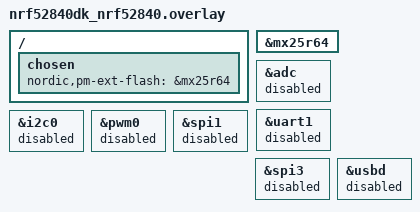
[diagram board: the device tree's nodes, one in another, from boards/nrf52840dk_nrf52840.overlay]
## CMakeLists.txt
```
#
# Copyright (c) 2025 Nordic Semiconductor ASA
#
# SPDX-License-Identifier: LicenseRef-Nordic-5-Clause
#

cmake_minimum_required(VERSION 3.20.0)

include(${CMAKE_CURRENT_LIST_DIR}/../../cmake/find_zephyr.cmake)

project(matter-temperature-sensor)

# NORDIC SDK APP START

# Include all source files that are located in the Matter common directory.
include(${ZEPHYR_NCS_MATTER_MODULE_DIR}/cmake/sample.cmake)

ncs_get_zap_parent_dir(ZAP_PARENT_DIR)

target_include_directories(app PRIVATE
  src
  ${ZAP_PARENT_DIR}
)

target_sources(app PRIVATE
  src/app_task.cpp
  src/main.cpp
)

ncs_configure_data_model()
# NORDIC SDK APP END
```

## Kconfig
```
#
# Copyright (c) 2025 Nordic Semiconductor
#
# SPDX-License-Identifier: LicenseRef-Nordic-5-Clause
#
mainmenu "Matter nRF Connect Temperature Sensor Example Application"

choice OPENTHREAD_NORDIC_LIBRARY_CONFIGURATION
	default OPENTHREAD_NORDIC_LIBRARY_MTD
endchoice

choice OPENTHREAD_DEVICE_TYPE
	default OPENTHREAD_MTD
endchoice

choice OPENTHREAD_IMPLEMENTATION
	default OPENTHREAD_SOURCES
endchoice

config CHIP_ENABLE_ICD_SUPPORT
	default y

config CHIP_ICD_LIT_SUPPORT
	default y

config CHIP_ICD_SIT_SLOW_POLL_LIMIT
	default 5000

config CHIP_ICD_REPORT_ON_ACTIVE_MODE
	default y

# Reduce Thread TX output power to 0 dBm for SED device
config OPENTHREAD_DEFAULT_TX_POWER
	default 0

source "$(ZEPHYR_CONNECTEDHOMEIP_MODULE_DIR)/config/nrfconnect/chip-module/Kconfig.features"
source "$(ZEPHYR_CONNECTEDHOMEIP_MODULE_DIR)/config/nrfconnect/chip-module/Kconfig.defaults"
source "Kconfig.zephyr"
```

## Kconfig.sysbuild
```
#
# Copyright (c) 2025 Nordic Semiconductor ASA
#
# SPDX-License-Identifier: LicenseRef-Nordic-5-Clause
#

#### Radio core selection
config NRF_DEFAULT_IPC_RADIO
	default y

# Enable IEEE802.15.4 serialization to network core
# This config automatically pulls in the `overlay-802154.conf` in the ipc_radio image
config NETCORE_IPC_RADIO_IEEE802154
	default y if SOC_SERIES_NRF53

# Enable Bluetooth serialization to network core
# This config automatically pulls in the `overlay-bt_hci_ipc.conf` in the ipc_radio image
config NETCORE_IPC_RADIO_BT_HCI_IPC
	default y if SOC_SERIES_NRF53

#### Bootloader
choice BOOTLOADER
	default BOOTLOADER_MCUBOOT if !BOARD_NATIVE_SIM
endchoice

if BOOTLOADER_MCUBOOT

#### DFU multi-image support
config DFU_MULTI_IMAGE_PACKAGE_BUILD
	default y

config DFU_MULTI_IMAGE_PACKAGE_APP
	default y

#### DFU network core configuration
if SOC_SERIES_NRF53

config MCUBOOT_UPDATEABLE_IMAGES
	default 2

choice MCUBOOT_MODE
	default MCUBOOT_MODE_OVERWRITE_ONLY
endchoice

choice BOOT_SIGNATURE_TYPE
	default BOOT_SIGNATURE_TYPE_RSA
endchoice

config SECURE_BOOT_NETCORE
	default y

config NETCORE_APP_UPDATE
	default y

config DFU_MULTI_IMAGE_PACKAGE_NET
	default y

endif # SOC_SERIES_NRF53

# Internal flash only for nRF54L15 tag with compression
if BOARD_NRF54L15TAG

choice MCUBOOT_MODE
	default MCUBOOT_MODE_OVERWRITE_ONLY
endchoice

config MCUBOOT_COMPRESSED_IMAGE_SUPPORT
	default y

endif

endif # BOOTLOADER_MCUBOOT

#### Enable generating factory data
config MATTER_ADD_ON_FACTORY_DATA_GENERATE
	default y if !BOARD_NATIVE_SIM

source "share/sysbuild/Kconfig"
```

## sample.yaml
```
sample:
  description: Matter Temperature Sensor example
  name: Matter Temperature Sensor
common:
  tags:
    - sysbuild
    - ci_samples_matter
tests:
  sample.matter.temperature_sensor.debug:
    sysbuild: true
    build_only: true
    integration_platforms:
      - nrf5340dk/nrf5340/cpuapp
      - nrf54l15dk/nrf54l15/cpuapp
      - nrf54l15tag/nrf54l15/cpuapp
      - nrf54lm20dk/nrf54lm20b/cpuapp
      - nrf54lm20dk/nrf54lm20a/cpuapp
    platform_allow:
      - nrf5340dk/nrf5340/cpuapp
      - nrf54l15dk/nrf54l15/cpuapp
      - nrf54l15tag/nrf54l15/cpuapp
      - nrf54lm20dk/nrf54lm20b/cpuapp
      - nrf54lm20dk/nrf54lm20a/cpuapp
  sample.matter.temperature_sensor.release:
    sysbuild: true
    build_only: true
    extra_args:
      - FILE_SUFFIX=release
    integration_platforms:
      - nrf54lm20dk/nrf54lm20b/cpuapp
      - nrf54lm20dk/nrf54lm20a/cpuapp
    platform_allow:
      - nrf5340dk/nrf5340/cpuapp
      - nrf54l15dk/nrf54l15/cpuapp
      - nrf54l15tag/nrf54l15/cpuapp
      - nrf54lm20dk/nrf54lm20b/cpuapp
      - nrf54lm20dk/nrf54lm20a/cpuapp
```

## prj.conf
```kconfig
#
# Copyright (c) 2025 Nordic Semiconductor ASA
#
# SPDX-License-Identifier: LicenseRef-Nordic-5-Clause
#

# Enable CHIP
CONFIG_CHIP=y
CONFIG_CHIP_PROJECT_CONFIG="src/chip_project_config.h"
CONFIG_CHIP_DEVICE_PRODUCT_NAME="Matter Temperature Sensor"

# Configure ZAP file name
CONFIG_MATTER_ZAP_FILE_PATH="${APPLICATION_CONFIG_DIR}/src/default_zap/temperature_sensor.zap"

# Based on https://github.com/project-chip/connectedhomeip/blob/482e6fd03196a6de45465a90003947ef4b86e0b1/docs/examples/discussion/PID_allocation_for_example_apps.md)
CONFIG_CHIP_DEVICE_PRODUCT_ID=32781
CONFIG_STD_CPP17=y

# Enable Matter pairing automatically on application start.
CONFIG_CHIP_ENABLE_PAIRING_AUTOSTART=y

# Enable Matter extended announcement and increase duration to 1 hour.
CONFIG_CHIP_BLE_EXT_ADVERTISING=y
CONFIG_CHIP_BLE_ADVERTISING_DURATION=60

# Add support for LEDs and buttons on Nordic development kits
CONFIG_DK_LIBRARY=y

# Bluetooth Low Energy configuration
CONFIG_BT_DEVICE_NAME="MatterTemperature"
CONFIG_BT_DEVICE_NAME_MAX=18

# Suspend devices when the CPU goes into sleep
CONFIG_PM_DEVICE=y

# Other settings
CONFIG_THREAD_NAME=y
CONFIG_MPU_STACK_GUARD=y
CONFIG_RESET_ON_FATAL_ERROR=n
CONFIG_CHIP_LIB_SHELL=y

# Reduce application size
CONFIG_USE_SEGGER_RTT=n

# Enable Factory Data feature
CONFIG_CHIP_FACTORY_DATA=y
CONFIG_CHIP_FACTORY_DATA_BUILD=y
```

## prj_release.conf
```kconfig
#
# Copyright (c) 2025 Nordic Semiconductor ASA
#
# SPDX-License-Identifier: LicenseRef-Nordic-5-Clause
#

# Enable CHIP
CONFIG_CHIP=y
CONFIG_CHIP_PROJECT_CONFIG="src/chip_project_config.h"
CONFIG_CHIP_DEVICE_PRODUCT_NAME="Matter Temperature Sensor"

# Configure ZAP file name
CONFIG_MATTER_ZAP_FILE_PATH="${APPLICATION_CONFIG_DIR}/src/default_zap/temperature_sensor.zap"

# Based on https://github.com/project-chip/connectedhomeip/blob/482e6fd03196a6de45465a90003947ef4b86e0b1/docs/examples/discussion/PID_allocation_for_example_apps.md)
CONFIG_CHIP_DEVICE_PRODUCT_ID=32781
CONFIG_STD_CPP17=y

# Enable Matter pairing automatically on application start.
CONFIG_CHIP_ENABLE_PAIRING_AUTOSTART=y

# Enable Matter extended announcement and increase duration to 1 hour.
CONFIG_CHIP_BLE_EXT_ADVERTISING=y
CONFIG_CHIP_BLE_ADVERTISING_DURATION=60

# Add support for LEDs and buttons on Nordic development kits
CONFIG_DK_LIBRARY=y

# Try to disable unused RAM blocks to reduce power consumption
CONFIG_RAM_POWER_DOWN_LIBRARY=y

# Bluetooth Low Energy configuration
CONFIG_BT_DEVICE_NAME="MatterTemperature"
CONFIG_BT_DEVICE_NAME_MAX=18

# Suspend devices when the CPU goes into sleep
CONFIG_PM_DEVICE=y

# Enable system reset on fatal error
CONFIG_RESET_ON_FATAL_ERROR=y

# Disable all debug features
CONFIG_USE_SEGGER_RTT=n
CONFIG_SHELL=n
CONFIG_OPENTHREAD_SHELL=n
CONFIG_CONSOLE=n
CONFIG_UART_CONSOLE=n
CONFIG_SERIAL=n
CONFIG_LOG=n
CONFIG_LOG_MODE_MINIMAL=n
CONFIG_ASSERT_VERBOSE=n
CONFIG_ASSERT_NO_FILE_INFO=y
CONFIG_PRINTK=n
CONFIG_PRINTK_SYNC=n
CONFIG_THREAD_NAME=n
CONFIG_BOOT_BANNER=n

# Enable Factory Data feature
CONFIG_CHIP_FACTORY_DATA=y
CONFIG_CHIP_FACTORY_DATA_BUILD=y

# Enable Watchdog
CONFIG_MATTER_WATCHDOG=y

# Enable LTO to decrease the flash usage.
CONFIG_LTO=y
CONFIG_ISR_TABLES_LOCAL_DECLARATION=y
```

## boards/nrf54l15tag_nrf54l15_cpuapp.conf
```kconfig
#
# Copyright (c) 2026 Nordic Semiconductor ASA
#
# SPDX-License-Identifier: LicenseRef-Nordic-5-Clause
#

# Use RTT console (tag has no UART; same as rtt-console snippet).
CONFIG_USE_SEGGER_RTT=y
CONFIG_CONSOLE=y
CONFIG_RTT_CONSOLE=y
CONFIG_SEGGER_RTT_BUFFER_SIZE_UP=4096

# Real sensor for the l15tag
CONFIG_I2C=y
CONFIG_SENSOR=y
CONFIG_BME680=y

# No NFC hardware (NFCT pins used as GPIO)
CONFIG_CHIP_NFC_ONBOARDING_PAYLOAD=n

# Enable Watchdog
CONFIG_MATTER_WATCHDOG=y

# Enable LTO to decrease the flash usage.
CONFIG_LTO=y
CONFIG_ISR_TABLES_LOCAL_DECLARATION=y

CONFIG_MATTER_USE_DEFAULT_BUTTON_HANDLER=n
```

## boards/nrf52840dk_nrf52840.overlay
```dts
/*
 * Copyright (c) 2025 Nordic Semiconductor ASA
 *
 * SPDX-License-Identifier: LicenseRef-Nordic-5-Clause
 */

#include <nrf52840_partitions.dtsi>

/ {
	chosen {
		nordic,pm-ext-flash = &mx25r64;
	};
};

&mx25r64 {
	status = "okay";
};

/* Disable unused peripherals to reduce power consumption */
&adc {
	status = "disabled";
};

&uart1 {
	status = "disabled";
};

&i2c0 {
	status = "disabled";
};

&pwm0 {
	status = "disabled";
};

&spi1 {
	status = "disabled";
};

&spi3 {
	status = "disabled";
};

&usbd {
	status = "disabled";
};
```

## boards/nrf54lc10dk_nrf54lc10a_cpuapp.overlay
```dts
/*
 * Copyright (c) 2026 Nordic Semiconductor ASA
 *
 * SPDX-License-Identifier: LicenseRef-Nordic-5-Clause
 */

#include <nrf54lc10_cpuapp_partitions.dtsi>

/ {
	aliases {
		/* Use watchdog wdt31 as the application watchdog */
		watchdog0 = &wdt31;
	};
};

&wdt31 {
	status = "okay";
};
```

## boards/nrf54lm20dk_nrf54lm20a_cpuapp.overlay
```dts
/*
 * Copyright (c) 2025 Nordic Semiconductor ASA
 *
 * SPDX-License-Identifier: LicenseRef-Nordic-5-Clause
 */

#include <nrf54lm20_cpuapp_partitions.dtsi>

/ {
	aliases {
		/* Use watchdog wdt31 as the application watchdog */
		watchdog0 = &wdt31;
	};

	chosen {
		nordic,pm-ext-flash = &mx25r64;
	};
};

&mx25r64 {
	status = "okay";
};

&wdt31 {
	status = "okay";
};
```

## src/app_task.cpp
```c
/*
 * Copyright (c) 2025 Nordic Semiconductor ASA
 *
 * SPDX-License-Identifier: LicenseRef-Nordic-5-Clause
 */

#include "app_task.h"

#include "app/matter_init.h"
#include "app/task_executor.h"
#include "board/board.h"
#include "clusters/identify.h"
#include "lib/core/CHIPError.h"

#include <app-common/zap-generated/attributes/Accessors.h>

#include <zephyr/logging/log.h>

#ifdef CONFIG_BME680
#include <zephyr/drivers/sensor.h>

const device *sBme688SensorDev = DEVICE_DT_GET_ONE(bosch_bme680);
#endif

LOG_MODULE_DECLARE(app, CONFIG_CHIP_APP_LOG_LEVEL);

using namespace ::chip;
using namespace ::chip::app;
using namespace ::chip::DeviceLayer;

namespace
{
constexpr chip::EndpointId kTemperatureSensorEndpointId = 1;

Nrf::Matter::IdentifyCluster sIdentifyCluster(kTemperatureSensorEndpointId);

#ifdef CONFIG_CHIP_ICD_UAT_SUPPORT
#ifdef CONFIG_MATTER_USE_DEFAULT_BUTTON_HANDLER
#define UAT_BUTTON_MASK DK_BTN3_MSK
#endif
#endif

#ifndef CONFIG_MATTER_USE_DEFAULT_BUTTON_HANDLER
constexpr int kSoftwareUpdateTimeout = 1500;
constexpr int kUatTimeout = 1500;
constexpr int kFactoryResetTimeout = 3000;
constexpr int kUatBlinkPeriod = 200;
ButtonState sBtnState = ButtonState::None;
k_timer sBtn1Timer;
#endif

} /* namespace */

void HandleUAT()
{
#ifdef CONFIG_CHIP_ICD_UAT_SUPPORT
	LOG_INF("ICD UserActiveMode has been triggered.");
	Server::GetInstance().GetICDManager().OnNetworkActivity();
#endif
}
/* nRF54T15 TAG has only a single button,
 * therefore the default handler for factory data and software update had to be overridden.
 * On other DK's only UAT is handled by the application.
 */
void AppTask::ButtonEventHandler(Nrf::ButtonState state, Nrf::ButtonMask hasChanged)
{
#ifdef CONFIG_MATTER_USE_DEFAULT_BUTTON_HANDLER
	if (UAT_BUTTON_MASK & state & hasChanged) {
		HandleUAT();
	}
#else
	if (DK_BTN1_MSK & hasChanged) {
		if (DK_BTN1_MSK & state) {
			LOG_INF("Release the button within %ums to trigger Software Update", kSoftwareUpdateTimeout);
			k_timer_start(&sBtn1Timer, K_MSEC(kSoftwareUpdateTimeout), K_NO_WAIT);
			sBtnState = ButtonState::SoftwareUpdate;
		} else {
			if (sBtnState == ButtonState::SoftwareUpdate) {
#ifndef CONFIG_MATTER_CUSTOM_BLUETOOTH_ADVERTISING
				if (Nrf::GetBoard().GetDeviceState() == Nrf::DeviceState::DeviceProvisioned) {
/* In this case we need to run only Bluetooth LE SMP advertising if it is available */
#ifdef CONFIG_CHIP_DFU_OVER_BT_SMP
					GetDFUOverSMP().StartServer();
#else
					LOG_INF("Software update is disabled");
#endif
				} else {
					/* In this case we start both Bluetooth LE SMP and Matter advertising at the
					 * same time */
					Nrf::GetBoard().StartBLEAdvertisement();
				}
#endif
			} else if (sBtnState == ButtonState::UAT) {
				HandleUAT();
			}
			/* Restore LED's state and cancel the timer */
			k_timer_stop(&sBtn1Timer);
			sBtnState = ButtonState::None;
			Nrf::GetBoard().RestoreAllLedsState();
			Nrf::GetBoard().RunLedStateHandler();
		}
	}
#endif
}
#ifndef CONFIG_MATTER_USE_DEFAULT_BUTTON_HANDLER
void ButtonTimerEventHandler()
{
	if (sBtnState == ButtonState::SoftwareUpdate) {
		LOG_INF("Release the button within %ums to trigger UAT", kUatTimeout);
		k_timer_start(&sBtn1Timer, K_MSEC(kUatTimeout), K_NO_WAIT);
		sBtnState = ButtonState::UAT;

		/* Turn off all LEDs before starting blink to make sure blink is coordinated. */
		Nrf::GetBoard().ResetAllLeds();
		Nrf::GetBoard().ForEachLED([](Nrf::LEDWidget &led) { led.Blink(kUatBlinkPeriod); });
	} else if (sBtnState == ButtonState::UAT) {
		LOG_INF("Factory reset has been triggered. Release button within %ums to cancel.",
			kFactoryResetTimeout);

		/* Start timer for sFactoryResetTimeout to allow user to cancel, if required. */
		k_timer_start(&sBtn1Timer, K_MSEC(kFactoryResetTimeout), K_NO_WAIT);
		sBtnState = ButtonState::None;

		Nrf::GetBoard().ForEachLED([](Nrf::LEDWidget &led) { led.Blink(Nrf::LedConsts::kBlinkRate_ms); });
		/* If we reached here, the button was held past FactoryResetTriggerTimeout, initiate factory reset */
	} else if (sBtnState == ButtonState::None) {
		/* Actually trigger Factory Reset */
		chip::Server::GetInstance().ScheduleFactoryReset();
	}
}

void ButtonTimerTimeoutCallback(k_timer *timer)
{
	Nrf::PostTask([] { ButtonTimerEventHandler(); });
}

#endif

void AppTask::UpdateTemperatureMeasurement()
{
#ifdef CONFIG_BME680
	/* Real data from the onboard sensor*/
	int result = sensor_sample_fetch(sBme688SensorDev);
	if (result == 0) {
		sensor_value temperature;
		int result = sensor_channel_get(sBme688SensorDev, SENSOR_CHAN_AMBIENT_TEMP, &temperature);
		if (result == 0) {
			/* Defined by cluster temperature measured value = 100 x temperature in degC with resolution of
			 * 0.01 degC. val1 is an integer part of the value and val2 is fractional part in one-millionth
			 * parts. To achieve resolution of 0.01 degC val2 needs to be divided by 10000. */
			mCurrentTemperature = static_cast<int16_t>(temperature.val1 * 100 + temperature.val2 / 10000);
			LOG_DBG("New temperature measurement %d.%d *C", temperature.val1, temperature.val2);
		} else {
			LOG_ERR("Getting temperature measurement data from BME688 failed with: %d", result);
		}
	} else {
		LOG_ERR("Fetching data from BME688 sensor failed with: %d", result);
	}
#else
	/* Linear temperature increase that is wrapped around to min value after reaching the max value. */
	if (mCurrentTemperature < mTemperatureSensorMaxValue) {
		mCurrentTemperature += kTemperatureMeasurementStep;
	} else {
		mCurrentTemperature = mTemperatureSensorMinValue;
	}
#endif
}

void AppTask::UpdateTemperatureTimeoutCallback(k_timer *timer)
{
	if (!timer || !timer->user_data) {
		return;
	}

	DeviceLayer::PlatformMgr().ScheduleWork(
		[](intptr_t p) {
			AppTask::Instance().UpdateTemperatureMeasurement();

			Protocols::InteractionModel::Status status =
				Clusters::TemperatureMeasurement::Attributes::MeasuredValue::Set(
					kTemperatureSensorEndpointId, AppTask::Instance().GetCurrentTemperature());

			if (status != Protocols::InteractionModel::Status::Success) {
				LOG_ERR("Updating temperature measurement failed %x", to_underlying(status));
			}
		},
		reinterpret_cast<intptr_t>(timer->user_data));
}

CHIP_ERROR AppTask::Init()
{
	/* Initialize Matter stack */
	ReturnErrorOnFailure(Nrf::Matter::PrepareServer());

	if (!Nrf::GetBoard().Init(ButtonEventHandler)) {
		LOG_ERR("User interface initialization failed.");
		return CHIP_ERROR_INCORRECT_STATE;
	}

	/* Register Matter event handler that controls the connectivity status LED based on the captured Matter network
	 * state. */
	ReturnErrorOnFailure(Nrf::Matter::RegisterEventHandler(Nrf::Board::DefaultMatterEventHandler, 0));
#ifdef CONFIG_BME680
	if (!device_is_ready(sBme688SensorDev)) {
		LOG_ERR("BME688 sensor device not ready");
		return chip::System::MapErrorZephyr(-ENODEV);
	}
#endif

	ReturnErrorOnFailure(sIdentifyCluster.Init());

	return Nrf::Matter::StartServer();
}

CHIP_ERROR AppTask::StartApp()
{
	ReturnErrorOnFailure(Init());

	DataModel::Nullable<int16_t> val;
	Protocols::InteractionModel::Status status =
		Clusters::TemperatureMeasurement::Attributes::MinMeasuredValue::Get(kTemperatureSensorEndpointId, val);

	if (status != Protocols::InteractionModel::Status::Success || val.IsNull()) {
		LOG_ERR("Failed to get temperature measurement min value %x", to_underlying(status));
		return CHIP_ERROR_INCORRECT_STATE;
	}

	mTemperatureSensorMinValue = val.Value();

	status = Clusters::TemperatureMeasurement::Attributes::MaxMeasuredValue::Get(kTemperatureSensorEndpointId, val);

	if (status != Protocols::InteractionModel::Status::Success || val.IsNull()) {
		LOG_ERR("Failed to get temperature measurement max value %x", to_underlying(status));
		return CHIP_ERROR_INCORRECT_STATE;
	}

	mTemperatureSensorMaxValue = val.Value();

	k_timer_init(&mTimer, AppTask::UpdateTemperatureTimeoutCallback, nullptr);
	k_timer_user_data_set(&mTimer, this);
	k_timer_start(&mTimer, K_MSEC(kTemperatureMeasurementIntervalMs), K_MSEC(kTemperatureMeasurementIntervalMs));
#ifndef CONFIG_MATTER_USE_DEFAULT_BUTTON_HANDLER
	k_timer_init(&sBtn1Timer, &ButtonTimerTimeoutCallback, nullptr);
#endif
	while (true) {
		Nrf::DispatchNextTask();
	}

	return CHIP_NO_ERROR;
}
```

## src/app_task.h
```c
/*
 * Copyright (c) 2025 Nordic Semiconductor ASA
 *
 * SPDX-License-Identifier: LicenseRef-Nordic-5-Clause
 */

#pragma once

#include "board/board.h"

#include <platform/CHIPDeviceLayer.h>

struct Identify;

#ifndef CONFIG_MATTER_USE_DEFAULT_BUTTON_HANDLER
enum class ButtonState { None, SoftwareUpdate, UAT };
#endif

class AppTask {
public:
	static AppTask &Instance()
	{
		static AppTask sAppTask;
		return sAppTask;
	};

	CHIP_ERROR StartApp();

	/* Defined by cluster temperature measured value = 100 x temperature in degC with resolution of
	 * 0.01 degC. */
	void UpdateTemperatureMeasurement();

	int16_t GetCurrentTemperature() const { return mCurrentTemperature; }

private:
	CHIP_ERROR Init();
	k_timer mTimer;

	static constexpr uint16_t kTemperatureMeasurementIntervalMs = 10000; /* 10 seconds */
	static constexpr uint16_t kTemperatureMeasurementStep = 100; /* 1 degree Celsius */

	static void UpdateTemperatureTimeoutCallback(k_timer *timer);

	static void ButtonEventHandler(Nrf::ButtonState state, Nrf::ButtonMask hasChanged);

	int16_t mTemperatureSensorMaxValue = 0;
	int16_t mTemperatureSensorMinValue = 0;
	int16_t mCurrentTemperature = 0;
};
```
